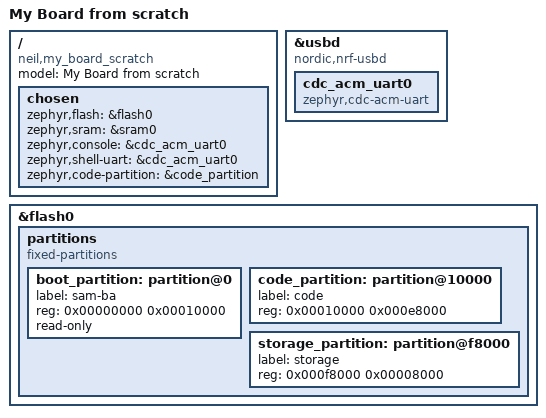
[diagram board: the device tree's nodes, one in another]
/dts-v1/;
#include <nordic/nrf52840_qiaa.dtsi>
//#include <dt-bindings/gpio/gpio.h>
//#include <zephyr/dt-bindings/pinctrl/nrf-pinctrl.h>
/{
    model= "My Board from scratch";
    compatible = "neil,my_board_scratch";

    chosen{
		zephyr,flash = &flash0;
		zephyr,sram = &sram0;
		zephyr,console = &cdc_acm_uart0;
		zephyr,shell-uart = &cdc_acm_uart0;
        zephyr,code-partition = &code_partition;
    };
    
    /*aliases {
		led0 = &led0;
		led1 = &led1;
		led2 = &led2;
		led3 = &led3;
		//led4 = &led4;
	};*/

    //zephyr,user {
	//	/* I2C pull-ups are connected to VDD via pin voltage level */
	//	pull-up-gpios = <&gpio1 0 GPIO_ACTIVE_HIGH>;
	//};
    
    //leds{
    //    compatible = "gpio-leds";
	//    led0: led_0 {
	//        gpios = <&gpio0 24 GPIO_ACTIVE_LOW>;
	//        label = "Red LED";
    //    };

	//    led1: led_1 {
    //	    gpios = <&gpio0 16 GPIO_ACTIVE_LOW>;
	//	    label = "Green LED";
	//    };

	//    led2: led_2 {
	//	    gpios = <&gpio0 6 GPIO_ACTIVE_LOW>;
	//	    label = "Blue LED";
	//    };

	//    led3: led_3 {
	//        /* Cannot be used together with spi2. */
	//	    gpios = <&gpio0 13 GPIO_ACTIVE_HIGH>;
	//	    label = "Yellow LED";
	//    };
    

	    //led4: led_4 {
    	//	gpios = <&gpio1 9 GPIO_ACTIVE_HIGH>;
		//    label = "User LED";
	    //};
    //};
    
};
    
//&gpio0 {
//    status = "okay";
//};

//&gpio1 {
//	status = "okay";
//};

//&gpiote {
//	status = "okay";
//};

   
//zephyr_udc0: &usbd {
&usbd {
    compatible = "nordic,nrf-usbd";
    status = "okay";
    cdc_acm_uart0: cdc_acm_uart0 {
        compatible = "zephyr,cdc-acm-uart";
    };
};
/*
&zephyr_udc0: &usbd {
    cdc_acm_uart0: cdc_acm_uart0 {
        compatible = "zephyr,cdc-acm-uart";
    };
};*/

/*&uart0 {
    compatible = "nordic,nrf-uarte";
    current-speed = <115200>;
    status = "okay";
    pinctrl-0 = <&uart0_default>;
    pinctrl-1 = <&uart0_sleep>;
    pinctrl-names = "default", "sleep";
};
*/
&flash0 {
    partitions {
        compatible = "fixed-partitions";
        #address-cells = <1>;
        #size-cells = <1>;

        boot_partition: partition@0 {
            label = "sam-ba";
            reg = <0x00000000 0x00010000>;
            read-only;
        };

        code_partition: partition@10000 {
            label = "code";
            reg = <0x00010000 0x000e8000>;
        };
       /*
        * The flash starting at 0x000f8000 and ending at
        * 0x000fffff is reserved for use by the application.
        * Storage partition will be used by FCB/LittleFS/NVS
        * if enabled.
        */
        storage_partition: partition@f8000 {
            label = "storage";
            reg = <0x000f8000 0x00008000>;
        };
	};
};

